# BE-U1000 register map
Vendor: BAIKAL ELECTRONICS, JSC; File version: 1.0
CPU: RISC-V r0p0, little endian, no MPU, no FPU, 3 interrupt priority bits
Registers are 32-bit, read-write, reset 0x0 unless marked. A register's access mark holds for its fields unless they carry their own. Offsets are from the block's base; [hi:lo] are bit positions; <NAME> marks a mode.

## GPIO0 — General Purpose I/O
Base 0x11009000
Same registers: GPIO1 0x13009000, GPIO2 0x14008000
0x00 DR — Data
  [15:0] DR — Port data value
0x04 DDR — Direction
  [15:0] DDR — Port data direction
0x30 INTEN — Interrupt enable
  [15:0] INTEN — Port bits interrupts enable
0x34 INTMSK — Interrupt mask
  [15:0] INTMSK — Port bits interrupt masking
0x38 INTLVL — Interrupt level
  [15:0] INTLVL — Port bits interrupt edge/level mode
0x3C INTPOLARITY — Interrupt polarity
  [15:0] INTPOLARITY — Polarity of edge or level sensitivity
0x40 INTSTAT — Interrupt status
  [15:0] INTSTAT — Interrupts status
0x44 INTSTATRAW — Raw interrupt status
  [15:0] INTSTATRAW — Raw interrupts status
0x48 DEBOUNCE — Debounce enable
  [15:0] DEBOUNCE
0x4C EOI — Clear interrupt
  [15:0] EOI — Clear interrupts
0x50 EXT — External port
  [15:0] EXT — Eternal port
0x60 SYNC — Synchronization level
  [0] SYNC
    0=DISABLE; 1=ENABLE
0x68 BOTHEDGE — Interrupt Both Edge type
  [15:0] BOTHEDGE — Both Edge type

## MB — Mailbox
Base 0x15103000
Same registers: MB1 0x15103020
0x00 DATA0
0x04 FULL0 — Data 0 ready register
  [0] FULL0 — Data 0 ready
    0=DISABLE; 1=ENABLE
0x08 EMPTY0 — Data 0 empty register
  [0] EMPTY0 — Data 0 empty
    0=DISABLE; 1=ENABLE
0x10 DATA1
0x14 FULL1 — Data 1 ready register
  [0] FULL1 — Data 1 ready
    0=DISABLE; 1=ENABLE
0x18 EMPTY1 — Data 1 empty register
  [0] EMPTY1 — Data 1 empty
    0=DISABLE; 1=ENABLE

## PWMG0 — General Purpose Timer
Base 0x1100A000
Same registers: PWMG1 0x1300A000
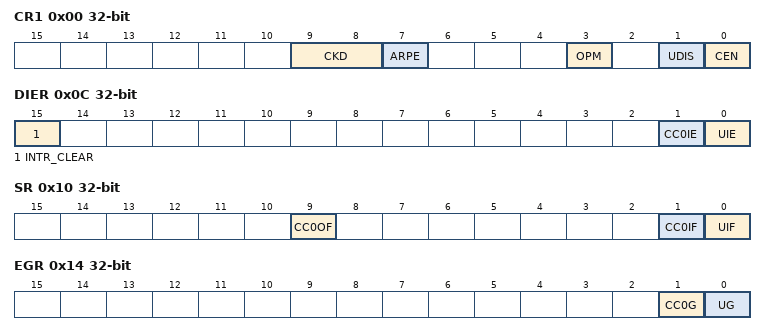
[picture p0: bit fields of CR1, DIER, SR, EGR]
0x00 CR1 — Control Register 1
  [9:8] CKD — Clock division
    0=DIV1 (Clock is not divided); 1=DIV2 (Clock is divided by 2); 2=DIV4 (Clock is divided by 4)
  [7] ARPE — Auto-reload preload enable
    0=DISABLE; 1=ENABLE
  [3] OPM — One pulse mode
    0=REPETITIVE (Counter is not stopped at update event); 1=SINGLE (Counter stops counting at the next update event)
  [1] UDIS — Update disable
    0=DISABLE; 1=ENABLE
  [0] CEN — Counter enable
    0=DISABLE; 1=ENABLE
0x0C DIER — DMA/Interrupt Enable Register
  [all] fields
    0=DISABLE; 1=ENABLE
  [15] INTR_CLEAR — Interrupt clear
  [1] CC0IE — Capture/Compare 0 interrupt enable
  [0] UIE — Update interrupt enable
0x10 SR — Status Register
  [all] fields
    0=DISABLE; 1=ENABLE
  [9] CC0OF — Capture/Compare 0 overcapture flag
  [1] CC0IF — Capture/Compare 0 interrupt flag
  [0] UIF — Update interrupt flag
0x14 EGR — Event Generation Register
  [1] CC0G — Capture/Compare 0 generation
    0=DISABLE; 1=ENABLE
  [0] UG — Update generation
    0=DISABLE; 1=ENABLE
0x18 CCMR1 — Capture/Compare mode register 1
  [1:0] CC0S — Capture/Compare 0 selection
    0=OC (Output Compare); 3=IC (Input Capture)
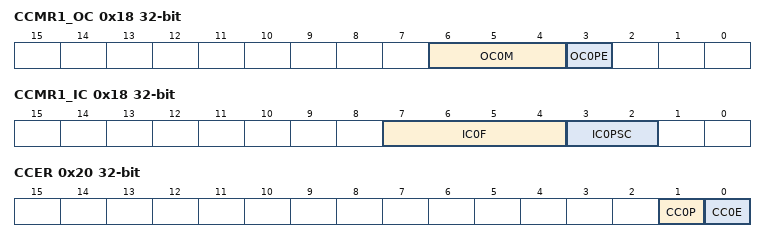
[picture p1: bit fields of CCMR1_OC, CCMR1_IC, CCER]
0x18 CCMR1_OC — Capture/Compare mode register 1, Output Compare
  [6:4] OC0M — Output Compare 0 mode
    0=FROZEN (The comparison between the output compare register CCR0 and the counter CNT has no effect on the output channel level); 1=ACTIVE (OC0REF is forced high on compare match); 2=INACTIVE (OC0REF is forced low on compare match); 3=TOGGLE (OC0REF toggles on compare match); 4=FORCED_INACTIVE (OC0REF is forced low); 5=FORCED_ACTIVE (OC0REF is forced high); 6=PWM1 (In upcounting, channel 0 is active as long as CNT <= CCR0, else inactive. In downcounting, channel 0 is inactive as long as CNT >= CCR0, else active.); 7=PWM2 (In upcounting, channel 0 is inactive as long as CNT <= CCR0, else active. In downcounting, channel 0 is active as long as CNT >= CCR0, else inactive.)
  [3] OC0PE — Output Compare 0 preload enable
    0=DISABLE; 1=ENABLE
0x18 CCMR1_IC — Capture/Compare mode register 1, Input Capture
  [7:4] IC0F — Input Capture 0 filter
    0=FDIV1 (No filter, sampling is done at fDTS); 1=FDIV1_N2 (fSAMPLING = fCK_INT, N = 2); 2=FDIV1_N4 (fSAMPLING = fCK_INT, N = 4); 3=FDIV1_N8 (fSAMPLING = fCK_INT, N = 8); 4=FDIV2_N6 (fSAMPLING = fDTS/2, N = 6); 5=FDIV2_N8 (fSAMPLING = fDTS/2, N = 8); 6=FDIV4_N6 (fSAMPLING = fDTS/4, N = 6); 7=FDIV4_N8 (fSAMPLING = fDTS/4, N = 8); 8=FDIV8_N6 (fSAMPLING = fDTS/8, N = 6); 9=FDIV8_N8 (fSAMPLING = fDTS/8, N = 8); 10=FDIV16_N5 (fSAMPLING = fDTS/16, N = 5); 11=FDIV16_N6 (fSAMPLING = fDTS/16, N = 6); 12=FDIV16_N8 (fSAMPLING = fDTS/16, N = 8); 13=FDIV32_N5 (fSAMPLING = fDTS/32, N = 5); 14=FDIV32_N6 (fSAMPLING = fDTS/32, N = 6); 15=FDIV32_N8 (fSAMPLING = fDTS/32, N = 8)
  [3:2] IC0PSC — Input Capture 0 prescaler
    0=DIV1 (Prescaler is not used); 1=DIV2 (Prescaler is 2); 2=DIV4 (Prescaler is 4); 3=DIV8 (Prescaler is 8)
0x20 CCER — Capture/Compare Enable Register
  [1] CC0P — Capture/Compare 0 output polarity
    0=HIGH (Output: active high); 1=LOW (Output: active low); 0=NONINVERTED (Input: not inverted/rising edge); 1=INVERTED (Input: inverted/falling edge)
  [0] CC0E — Capture/Compare 0 output enable
    0=DISABLE; 1=ENABLE
0x24 CNT — Counter Register
  [15:0] CNT — Counter value
0x28 PSC — Prescaler Register
  [15:0] PSC — Prescaler value
0x2C ARR — Auto-Reload Register
  [15:0] ARR — Auto-reload value
0x34 CCR0 — Capture/Compare Register 0
  [15:0] CCR0 — Capture/Compare 0 value
